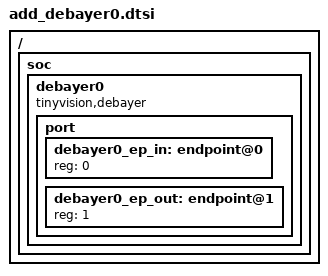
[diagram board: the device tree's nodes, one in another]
/*
 * Copyright (c) 2024-2025 tinyVision.ai Inc.
 *
 * SPDX-License-Identifier: Apache-2.0
 */

/ {
	soc {
		debayer0: debayer0 {
			compatible = "tinyvision,debayer";

			port {
				#address-cells = <1>;
				#size-cells = <0>;

				debayer0_ep_in: endpoint@0 {
					reg = <0>;
				};

				debayer0_ep_out: endpoint@1 {
					reg = <1>;
				};
			};
		};
	};
};
